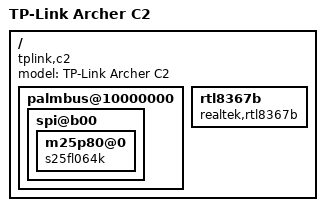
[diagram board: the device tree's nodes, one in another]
/dts-v1/;

/include/ "ArcherC2.dtsi"

/ {
	compatible = "tplink,c2", "ralink,mt7620a-soc";
	model = "TP-Link Archer C2";

	palmbus@10000000 {
		spi@b00 {
			m25p80@0 {
				compatible = "s25fl064k";
			};
		};
	};

	rtl8367b {
		compatible = "realtek,rtl8367b";
	};
};
